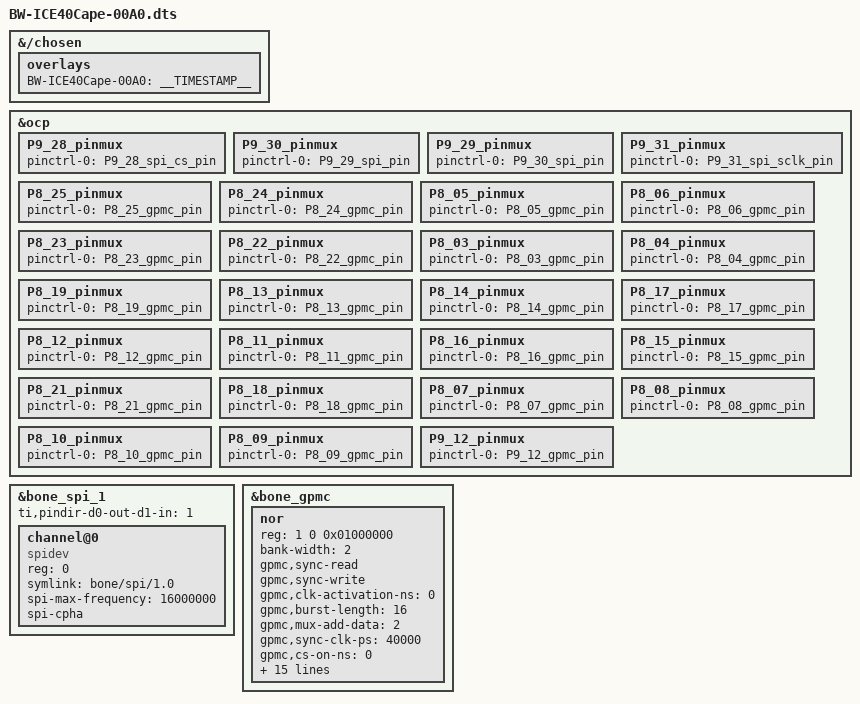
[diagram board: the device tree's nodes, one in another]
// SPDX-License-Identifier: GPL-2.0-only
/*
 * Copyright (C) 2021 Omkar Bhilare <ombhilare999@gmail.com>
 * See Cape Interface Spec page for more info on Bone Buses
 */

/dts-v1/;
/plugin/;

/*
* Helper to show loaded overlays under: /proc/device-tree/chosen/overlays/
*/
&{/chosen} {
    overlays {
        BW-ICE40Cape-00A0 = __TIMESTAMP__;
    };
};

/*
 * Update the default pinmux of the pins.
 * See these files for the phandles (&P9_* & &P8_*)
 * BeagleBoard-DeviceTrees/v4.19.x-ti-overlays/src/arm/am335x-bone-common-univ.dtsi
 * BeagleBoard-DeviceTrees/v4.19.x-ti-overlays/src/arm/am572x-bone-common-univ.dtsi
 */
&ocp {
    P9_28_pinmux { pinctrl-0 = <&P9_28_spi_cs_pin>; }; /* CS */
    P9_30_pinmux { pinctrl-0 = <&P9_29_spi_pin>; }; /* MOSI */
    P9_29_pinmux { pinctrl-0 = <&P9_30_spi_pin>; }; /* MISO */
    P9_31_pinmux { pinctrl-0 = <&P9_31_spi_sclk_pin>; }; /* CLK */
    P8_25_pinmux { pinctrl-0 = <&P8_25_gpmc_pin>; }; /* bw_gpmc_ad0 */
    P8_24_pinmux { pinctrl-0 = <&P8_24_gpmc_pin>; }; /* bw_gpmc_ad1 */
    P8_05_pinmux { pinctrl-0 = <&P8_05_gpmc_pin>; }; /* bw_gpmc_ad2 */
    P8_06_pinmux { pinctrl-0 = <&P8_06_gpmc_pin>; }; /* bw_gpmc_ad3 */
    P8_23_pinmux { pinctrl-0 = <&P8_23_gpmc_pin>; }; /* bw_gpmc_ad4 */
    P8_22_pinmux { pinctrl-0 = <&P8_22_gpmc_pin>; }; /* bw_gpmc_ad5 */
    P8_03_pinmux { pinctrl-0 = <&P8_03_gpmc_pin>; }; /* bw_gpmc_ad6 */
    P8_04_pinmux { pinctrl-0 = <&P8_04_gpmc_pin>; }; /* bw_gpmc_ad7 */
    P8_19_pinmux { pinctrl-0 = <&P8_19_gpmc_pin>; }; /* bw_gpmc_ad8 */
    P8_13_pinmux { pinctrl-0 = <&P8_13_gpmc_pin>; }; /* bw_gpmc_ad9 */
    P8_14_pinmux { pinctrl-0 = <&P8_14_gpmc_pin>; }; /* bw_gpmc_ad10 */
    P8_17_pinmux { pinctrl-0 = <&P8_17_gpmc_pin>; }; /* bw_gpmc_ad11*/
    P8_12_pinmux { pinctrl-0 = <&P8_12_gpmc_pin>; }; /* bw_gpmc_ad12 */
    P8_11_pinmux { pinctrl-0 = <&P8_11_gpmc_pin>; }; /* bw_gpmc_ad13 */
    P8_16_pinmux { pinctrl-0 = <&P8_16_gpmc_pin>; }; /* bw_gpmc_ad14 */
    P8_15_pinmux { pinctrl-0 = <&P8_15_gpmc_pin>; }; /* bw_gpmc_ad15 */
    P8_21_pinmux { pinctrl-0 = <&P8_21_gpmc_pin>; }; /* bw_gpmc_csn1 */
    P8_18_pinmux { pinctrl-0 = <&P8_18_gpmc_pin>; }; /* bw_gpmc_clk  */
    P8_07_pinmux { pinctrl-0 = <&P8_07_gpmc_pin>; }; /* bw_gpmc_advn_ale */
    P8_08_pinmux { pinctrl-0 = <&P8_08_gpmc_pin>; }; /* bw_gpmc_oen_ren */
    P8_10_pinmux { pinctrl-0 = <&P8_10_gpmc_pin>; }; /* bw_gpmc_wen */
    P8_09_pinmux { pinctrl-0 = <&P8_09_gpmc_pin>; }; /* bw_gpmc_be0n_cle*/
    P9_12_pinmux { pinctrl-0 = <&P9_12_gpmc_pin>; }; /* bw_gpmc_be1n */
};

/*
 * See these files for the phandles (&bone_*) and other bone bus nodes
 * BeagleBoard-DeviceTrees/v4.19.x-ti-overlays/src/arm/bbai-bone-buses.dtsi
 * BeagleBoard-DeviceTrees/v4.19.x-ti-overlays/src/arm/bbb-bone-buses.dtsi
 */
&bone_spi_1 {
    status = "okay";
    #address-cells = <1>;
    #size-cells = <0>;
    ti,pindir-d0-out-d1-in = <1>;
    channel@0 {
        reg = <0>;
        compatible = "spidev";
        symlink = "bone/spi/1.0";
        spi-max-frequency = <16000000>;
        spi-cpha;
    };
};

&bone_gpmc{

    status = "okay";

    #address-cells = <2>;
    #size-cells = <1>;

    /* chip select ranges */
    ranges = <1 0 0x01000000 0x1000000>;

    nor {

        reg = <1 0 0x01000000>;         /*CSn1*/
        bank-width = <2>;               /* GPMC_CONFIG1_DEVICESIZE(1) */

        /*gpmc,burst-write;
        gpmc,burst-read;
        gpmc,burst-wrap;*/
        gpmc,sync-read;                 /* GPMC_CONFIG1_READTYPE_ASYNC */
        gpmc,sync-write;                /* GPMC_CONFIG1_WRITETYPE_ASYNC */
        gpmc,clk-activation-ns = <0>;   /* GPMC_CONFIG1_CLKACTIVATIONTIME(2) */
        gpmc,burst-length = <16>;       /* GPMC_CONFIG1_PAGE_LEN(2) */
        gpmc,mux-add-data = <2>;        /* GPMC_CONFIG1_MUXTYPE(2) */

        /* CONFIG2 */
        gpmc,sync-clk-ps = <40000>;
        gpmc,cs-on-ns = <0>;
        gpmc,cs-rd-off-ns = <200>;
        gpmc,cs-wr-off-ns = <200>;

        /* CONFIG3 */
        gpmc,adv-on-ns = <0>;
        gpmc,adv-rd-off-ns = <80>;
        gpmc,adv-wr-off-ns = <80>;

        /* CONFIG4 */
        gpmc,we-on-ns = <40>;
        gpmc,we-off-ns = <200>;
        gpmc,oe-on-ns = <40>;
        gpmc,oe-off-ns = <200>;

        /* CONFIG 5 */
        gpmc,page-burst-access-ns = <40>;
        gpmc,access-ns = <200>;
        gpmc,rd-cycle-ns = <280>;
        gpmc,wr-cycle-ns = <280>;

        /* CONFIG 6 */
        gpmc,wr-access-ns = <40>;
        gpmc,wr-data-mux-bus-ns = <40>;
        /*gpmc,bus-turnaround-ns = <40>;*/  /* CONFIG6:3:0 = 4 */
        /*gpmc,cycle2cycle-samecsen;*/      /* CONFIG6:7 = 1 */
        /*gpmc,cycle2cycle-delay-ns = <40>;*/   /* CONFIG6:11:8 = 4 */
    };
};
